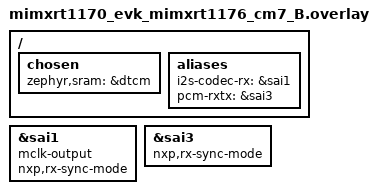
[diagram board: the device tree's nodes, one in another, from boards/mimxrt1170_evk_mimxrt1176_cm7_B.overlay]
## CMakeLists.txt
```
#SPDX - License - Identifier : Apache - 2.0

cmake_minimum_required(VERSION 3.28.0)
find_package(Zephyr REQUIRED HINTS $ENV{ZEPHYR_BASE})
project(handsfree_ag)

FILE(GLOB app_sources src/*.c)
target_sources(app PRIVATE ${app_sources})

include(${CMAKE_CURRENT_SOURCE_DIR}/../common/common.cmake)

zephyr_library_include_directories(${ZEPHYR_BASE}/samples/bluetooth)
```

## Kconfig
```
#
# Copyright 2024-2025 NXP
#
# SPDX-License-Identifier: Apache-2.0
#

mainmenu "Bluetooth: handsfree AG"

config BT_HFP_AG_DISCOVER_RESULT_COUNT
	int "Maximum result count per device discovery"
	default 10

config BT_HFP_AG_CALL_OUTGOING
	bool "The simulate call: outgoing (y), incoming (n)"

config BT_HFP_AG_START_CALL_DELAY_TIME
	int "The delay time used to start simulating a call after AG connection"
	default 5000
	help
	  The Delay time is used to wait for the peer to start dialing. If the
	  peer does not dial within the timeout period, AG satrt simulating a
	  call. The unit is ms.

source "Kconfig.zephyr"

choice HFP_AUDIO_PATH
	prompt "HFP audio data path"
	default HFP_AUDIO_PATH_SCO_HCI if SOC_SERIES_SF32LB52X
	default HFP_AUDIO_PATH_PCM
	help
	  Select the audio data path used for HFP voice streaming.

config HFP_AUDIO_PATH_PCM
	bool "PCM/I2S interface to controller"
	help
	  Route voice data through PCM/I2S pins on the Bluetooth controller.
	  Requires devicetree aliases for pcm-rxtx or pcm-rx/pcm-tx and
	  i2s-codec-rx/i2s-codec-tx.

config HFP_AUDIO_PATH_SCO_HCI
	bool "SCO over HCI transport"
	select BT_SCO_OVER_HCI
	help
	  Route voice data as SCO packets over the HCI transport between
	  the host and controller. Required for controllers without PCM pins,
	  such as the SiFli SF32LB52.

endchoice

config HFP_SCO_HCI_MSBC
	bool "Enable mSBC wideband codec for SCO over HCI"
	depends on HFP_AUDIO_PATH_SCO_HCI
	select LIBSBC
	default y if BT_HFP_AG_CODEC_MSBC
	help
	  Enable mSBC encode/decode for wideband voice when the SCO air mode
	  is transparent. Requires CONFIG_BT_HFP_AG_CODEC_NEG and
	  CONFIG_BT_HFP_AG_CODEC_MSBC for codec negotiation with the peer.

config HFP_SCO_HCI_THREAD_STACK_SIZE
	int "SCO over HCI audio thread stack size"
	depends on HFP_AUDIO_PATH_SCO_HCI
	default 2048

config HFP_SCO_HCI_THREAD_PRIO
	int "SCO over HCI audio thread priority"
	depends on HFP_AUDIO_PATH_SCO_HCI
	default 4

config AUDIO_TRANSFER_INTERVAL
	int "Audio transfer interval"
	default 10
	range 1 100
	help
	  Controls the audio transfer interval.

config PCM_BUFFERS
	int "PCM Buffer Count"
	default 4
	help
	  Controls the initial count of audio data blocks.

config PCM_RX_THREAD_STACK_SIZE
	int "PCM RX thread stack size"
	default 1024
	help
	  Controls the PCM RX thread stack size in bytes.

config PCM_RX_THREAD_PRIO
	int "PCM RX thread priority"
	default 4
	help
	  Controls the PCM RX thread priority.

config CODEC_BUFFERS
	int "CODEC Buffer Count"
	default PCM_BUFFERS
	help
	  Controls the initial count of audio data blocks.

config CODEC_RX_THREAD_STACK_SIZE
	int "CODEC RX thread stack size"
	default 1024
	help
	  Controls the CODEC RX thread stack size in bytes.

config CODEC_RX_THREAD_PRIO
	int "CODEC RX thread priority"
	default 4
	help
	  Controls the CODEC RX thread priority.
```

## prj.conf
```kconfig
CONFIG_BT=y
CONFIG_BT_CLASSIC=y
CONFIG_BT_RFCOMM=y
CONFIG_BT_HFP_AG=y
CONFIG_BT_CENTRAL=y
CONFIG_BT_DEVICE_NAME="Handsfree-ag"
```

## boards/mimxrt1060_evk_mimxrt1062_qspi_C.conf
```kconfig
CONFIG_AUDIO=y
CONFIG_I2S=y
CONFIG_AUDIO_CODEC=y

CONFIG_BT_HFP_AG_CODEC_NEG=y
CONFIG_BT_HFP_AG_CODEC_MSBC=y

CONFIG_DMA_MCUX_USE_DTCM_FOR_DMA_DESCRIPTORS=n
```

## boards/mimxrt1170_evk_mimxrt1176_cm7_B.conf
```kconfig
#select NXP NW612 Chipset
CONFIG_BT_NXP_NW612=y

CONFIG_I2S=y
CONFIG_AUDIO=y
CONFIG_AUDIO_CODEC=y

CONFIG_BT_HFP_AG_CODEC_NEG=y
CONFIG_BT_HFP_AG_CODEC_MSBC=y

CONFIG_DMA_MCUX_USE_DTCM_FOR_DMA_DESCRIPTORS=n
```

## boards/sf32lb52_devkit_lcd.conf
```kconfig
CONFIG_BT_CLASSIC=y
CONFIG_BT_RFCOMM=y
CONFIG_BT_HFP_AG=y
CONFIG_BT_CENTRAL=y
CONFIG_BT_DEVICE_NAME="test-Handsfree-AG"
CONFIG_BT_COD=0x400408

CONFIG_BT_SCO_OVER_HCI=y
CONFIG_BT_HFP_AG_CODEC_NEG=y
CONFIG_BT_HFP_AG_CODEC_MSBC=y
CONFIG_HFP_SCO_HCI_MSBC=y
CONFIG_LIBSBC=y
CONFIG_HEAP_MEM_POOL_SIZE=32000
CONFIG_AUDIO=y
CONFIG_AUDIO_CODEC=y
CONFIG_CRC_HW_HANDLER=n
```

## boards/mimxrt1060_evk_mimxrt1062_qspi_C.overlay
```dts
/*
 * SPDX-FileCopyrightText: Copyright The Zephyr Project Contributors
 *
 * SPDX-License-Identifier: Apache-2.0
 */

/ {
	aliases {
		i2s-codec-rx = &sai1;
		pcm-rxtx = &sai2;
	};
};

/* SAI1 already has pinctrl-0 set in board dtsi, just add our properties */
&sai1 {
	status = "okay";
	mclk-output;
	nxp,rx-sync-mode;
};

/*
 * SAI2 has pinctrl set in board dtsi, Enable SAI2 as duplex PCM interface
 * for HFP SCO audio
 */
&sai2 {
	status = "okay";
	nxp,tx-channel = <1>;
	nxp,rx-sync-mode;
};
```

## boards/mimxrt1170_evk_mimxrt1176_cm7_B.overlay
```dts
/*
 * Copyright 2024-2025 NXP
 *
 * SPDX-License-Identifier: Apache-2.0
 */

/ {
	chosen {
		zephyr,sram = &dtcm;
	};

	aliases {
		i2s-codec-rx = &sai1;
		pcm-rxtx = &sai3;
	};
};

&sai1 {
	mclk-output;
	nxp,rx-sync-mode;
	status = "okay";
};

&sai3 {
	nxp,rx-sync-mode;
	status = "okay";
};
```

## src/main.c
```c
/* main.c - Application main entry point */

/*
 * Copyright 2024-2026 NXP
 *
 * SPDX-License-Identifier: Apache-2.0
 */

#include <zephyr/types.h>
#include <stddef.h>
#include <string.h>
#include <errno.h>
#include <zephyr/sys/printk.h>
#include <zephyr/sys/byteorder.h>
#include <zephyr/kernel.h>

#include <zephyr/bluetooth/bluetooth.h>
#include <zephyr/bluetooth/conn.h>
#include <zephyr/bluetooth/l2cap.h>
#include <zephyr/bluetooth/hci.h>
#include <zephyr/bluetooth/classic/rfcomm.h>
#include <zephyr/bluetooth/classic/sdp.h>
#include <zephyr/bluetooth/classic/hfp_ag.h>
#include <zephyr/settings/settings.h>

#if defined(CONFIG_HFP_AUDIO_PATH_SCO_HCI)
#include "sco_hci.h"
#else
#include "pcm.h"
#include "codec.h"
#endif

static struct bt_conn *default_conn;
static struct bt_hfp_ag *hfp_ag;
static struct bt_conn *active_sco_conn;
static struct bt_hfp_ag_call *hfp_ag_call;

static struct bt_br_discovery_param br_discover;
static struct bt_br_discovery_result scan_result[CONFIG_BT_HFP_AG_DISCOVER_RESULT_COUNT];

static struct k_work discover_work;
static struct k_work_delayable call_connect_work;
static struct k_work_delayable call_disconnect_work;

static struct k_work_delayable call_remote_ringing_work;
static struct k_work_delayable call_remote_accept_work;

NET_BUF_POOL_DEFINE(sdp_discover_pool, 10, BT_L2CAP_BUF_SIZE(CONFIG_BT_L2CAP_TX_MTU),
		    CONFIG_BT_CONN_TX_USER_DATA_SIZE, NULL);

static void ag_connected(struct bt_conn *conn, struct bt_hfp_ag *ag)
{
	if (conn != default_conn) {
		printk("The conn %p is not aligned with ACL conn %p", conn, default_conn);
	}

	if (!hfp_ag) {
		hfp_ag = ag;
	}
	printk("HFP AG connected!\n");
	k_work_schedule(&call_connect_work, K_MSEC(CONFIG_BT_HFP_AG_START_CALL_DELAY_TIME));
}

static void ag_disconnected(struct bt_hfp_ag *ag)
{
	printk("HFP AG disconnected!\n");
}

#if !defined(CONFIG_HFP_AUDIO_PATH_SCO_HCI)
static void pcm_rx_cb(const uint8_t *data, uint32_t len)
{
	int err;

	if (active_sco_conn == NULL) {
		return;
	}

	err = codec_tx(data, len);
	if (err != 0) {
		printk("Failed to transmit PCM data: %d\n", err);
	}
}

static void codec_rx_cb(const uint8_t *data, uint32_t len)
{
	int err;

	if (active_sco_conn == NULL) {
		return;
	}

	err = pcm_tx(data, len);
	if (err != 0) {
		printk("Failed to transmit Codec data: %d\n", err);
	}
}
#endif /* !CONFIG_HFP_AUDIO_PATH_SCO_HCI */

static void ag_sco_connected(struct bt_hfp_ag *ag, struct bt_conn *sco_conn)
{
	struct bt_conn_info info;
	int err;

	printk("AG SCO connected\n");
	active_sco_conn = bt_conn_ref(sco_conn);

	err = bt_conn_get_info(sco_conn, &info);
	if (err != 0) {
		printk("Failed to get sco conn %p info\n", sco_conn);
		return;
	}

	printk("SCO air mode %u\n", info.sco.air_mode);

#if defined(CONFIG_HFP_AUDIO_PATH_SCO_HCI)
	err = sco_hci_init(info.sco.air_mode);
	if (err != 0) {
		printk("Failed to initialize SCO over HCI for air mode %u\n", info.sco.air_mode);
		return;
	}

	err = sco_hci_start(sco_conn);
	if (err != 0) {
		printk("Failed to start SCO over HCI\n");
		return;
	}
#else
	err = pcm_init(info.sco.air_mode);
	if (err != 0) {
		printk("Failed to initialize PCM for air mode %u\n", info.sco.air_mode);
		return;
	}

	err = codec_init(info.sco.air_mode);
	if (err != 0) {
		printk("Failed to initialize CODEC for air mode %u\n", info.sco.air_mode);
		return;
	}

	err = pcm_rx_start(pcm_rx_cb);
	if (err != 0) {
		printk("Failed to start PCM\n");
		return;
	}

	err = codec_rx_start(codec_rx_cb);
	if (err != 0) {
		printk("Failed to start CODEC\n");
		return;
	}
#endif
}

static void ag_sco_disconnected(struct bt_conn *sco_conn, uint8_t reason)
{
	int err;

	if (active_sco_conn != sco_conn) {
		return;
	}

	bt_conn_drop(&active_sco_conn);

#if defined(CONFIG_HFP_AUDIO_PATH_SCO_HCI)
	err = sco_hci_stop();
	if (err != 0) {
		printk("Failed to stop SCO over HCI\n");
	}
#else
	err = pcm_rx_stop();
	if (err != 0) {
		printk("Failed to stop PCM\n");
	}

	err = codec_rx_stop();
	if (err != 0) {
		printk("Failed to stop CODEC\n");
	}
#endif

	printk("HFP AG SCO disconnected %u!\n", reason);
}

static void ag_ringing(struct bt_hfp_ag_call *call, bool in_band)
{
	printk("Ringing (in bond? %s)\n", in_band ? "Yes" : "No");
}

static void ag_accept(struct bt_hfp_ag_call *call)
{
	printk("Call Accepted\n");
	/* Keep the simulated call up long enough to verify SCO audio */
	k_work_schedule(&call_disconnect_work, K_SECONDS(60));
}

static void ag_reject(struct bt_hfp_ag_call *call)
{
	printk("Call Rejected\n");
	k_work_schedule(&call_disconnect_work, K_SECONDS(1));
}

static void ag_terminate(struct bt_hfp_ag_call *call)
{
	printk("Call terminated\n");
	k_work_schedule(&call_disconnect_work, K_SECONDS(1));
}

static void ag_outgoing(struct bt_hfp_ag *ag, struct bt_hfp_ag_call *call, const char *number)
{
	hfp_ag_call = call;
	printk("Call outgoing, remote number %s\n", number);
	k_work_cancel_delayable(&call_connect_work);
	k_work_schedule(&call_remote_ringing_work, K_SECONDS(1));
}

static void ag_incoming(struct bt_hfp_ag *ag, struct bt_hfp_ag_call *call, const char *number)
{
	hfp_ag_call = call;
	printk("Incoming call, remote number %s\n", number);
	k_work_cancel_delayable(&call_connect_work);
}

#if defined(CONFIG_BT_HFP_AG_CODEC_NEG)
static void ag_codec(struct bt_hfp_ag *ag, uint32_t ids)
{
	printk("AG received codec id bit map %x\n", ids);
}

static void ag_codec_negotiate(struct bt_hfp_ag *ag, int err)
{
	printk("AG codec negotiation result %d\n", err);
}
#endif /* CONFIG_BT_HFP_AG_CODEC_NEG */

static struct bt_hfp_ag_cb ag_cb = {
	.connected = ag_connected,
	.disconnected = ag_disconnected,
	.sco_connected = ag_sco_connected,
	.sco_disconnected = ag_sco_disconnected,
	.outgoing = ag_outgoing,
	.incoming = ag_incoming,
	.ringing = ag_ringing,
	.accept = ag_accept,
	.reject = ag_reject,
	.terminate = ag_terminate,
#if defined(CONFIG_BT_HFP_AG_CODEC_NEG)
	.codec = ag_codec,
	.codec_negotiate = ag_codec_negotiate,
#endif /* CONFIG_BT_HFP_AG_CODEC_NEG */
};

static uint8_t sdp_discover_cb(struct bt_conn *conn, struct bt_sdp_client_result *result,
			       const struct bt_sdp_discover_params *params)
{
	int err;
	uint16_t value;

	printk("Discover done\n");

	if (result->resp_buf != NULL) {
		err = bt_sdp_get_proto_param(result->resp_buf, BT_SDP_PROTO_RFCOMM, &value);

		if (err != 0) {
			printk("Fail to parser RFCOMM the SDP response!\n");
		} else {
			printk("The server channel is %d\n", value);
			err = bt_hfp_ag_connect(conn, &hfp_ag, value);
			if (err != 0) {
				printk("Fail to create hfp AG connection (err %d)\n", err);
			}
		}
	}

	return BT_SDP_DISCOVER_UUID_STOP;
}

static struct bt_sdp_discover_params sdp_discover = {
	.type = BT_SDP_DISCOVER_SERVICE_SEARCH_ATTR,
	.func = sdp_discover_cb,
	.pool = &sdp_discover_pool,
	.uuid = BT_UUID_DECLARE_16(BT_SDP_HANDSFREE_SVCLASS),
};

static void connected(struct bt_conn *conn, uint8_t err)
{
	int res;

	if (err) {
		if (default_conn != NULL) {
			default_conn = NULL;
		}
		printk("Connection failed, err 0x%02x %s\n", err, bt_hci_err_to_str(err));
	} else {
		if (default_conn == conn) {
			struct bt_conn_info info;

			bt_conn_get_info(conn, &info);
			if (info.type != BT_CONN_TYPE_BR) {
				return;
			}

			/*
			 * Do an SDP Query on Successful ACL connection complete with the
			 * required device
			 */
			res = bt_sdp_discover(default_conn, &sdp_discover);
			if (res) {
				printk("SDP discovery failed (err %d)\r\n", res);
			} else {
				printk("SDP discovery started\r\n");
			}
			printk("Connected\n");
		}
	}
}

static void disconnected(struct bt_conn *conn, uint8_t reason)
{
	printk("Disconnected, reason 0x%02x %s\n", reason, bt_hci_err_to_str(reason));

	if (default_conn != conn) {
		return;
	}

	if (default_conn) {
		default_conn = NULL;
	} else {
		return;
	}
}

static void security_changed(struct bt_conn *conn, bt_security_t level, enum bt_security_err err)
{
	struct bt_conn_info info;

	bt_conn_get_info(conn, &info);

	printk("Security changed: %s level %u, err %s(%d)\n", bt_addr_str(info.br.dst), level,
	       bt_security_err_to_str(err), err);
}

static struct bt_conn_cb conn_callbacks = {
	.connected = connected,
	.disconnected = disconnected,
	.security_changed = security_changed,
};

static void discovery_recv_cb(const struct bt_br_discovery_result *result)
{
	(void)result;
}

static void discovery_timeout_cb(const struct bt_br_discovery_result *results, size_t count)
{
	const struct bt_br_discovery_result *best_hf = NULL;
	static uint8_t temp[240];
	size_t i;

	for (i = 0; i < count; i++) {
		const uint8_t *eir = results[i].eir;
		size_t len = sizeof(results[i].eir);
		uint8_t major_device = (uint8_t)BT_COD_MAJOR_DEVICE_CLASS(results[i].cod);
		uint8_t minor_device = (uint8_t)BT_COD_MINOR_DEVICE_CLASS(results[i].cod);
		bool is_hf = (major_device & BT_COD_MAJOR_DEVICE_CLASS_AUDIO_VIDEO) &&
			     (minor_device & BT_COD_MINOR_DEVICE_CLASS_AUDIO_VIDEO_HANDSFREE);

		printk("Device[%d]: %s, rssi %d, cod 0x%02x%02x%02x", i,
		       bt_addr_str(&results[i].addr), results[i].rssi,
		       results[i].cod[0], results[i].cod[1], results[i].cod[2]);

		while ((eir[0] > 2) && (len > eir[0])) {
			switch (eir[1]) {
			case BT_DATA_NAME_SHORTENED:
			case BT_DATA_NAME_COMPLETE:
				memcpy(temp, &eir[2], eir[0] - 1);
				temp[eir[0] - 1] = '\0'; /* Set end flag */
				printk(", name %s", temp);
				break;
			default:
				/* Skip the EIR */
				break;
			}
			len = len - eir[0] - 1;
			eir = eir + eir[0] + 1;
		}
		printk("%s\n", is_hf ? ", Handsfree" : "");

		if (is_hf && (best_hf == NULL || results[i].rssi > best_hf->rssi)) {
			best_hf = &results[i];
		}
	}

	if (best_hf == NULL) {
		(void)k_work_submit(&discover_work);
		return;
	}

	(void)k_work_cancel(&discover_work);
	printk("Connecting to Handsfree %s (rssi %d)\n", bt_addr_str(&best_hf->addr),
	       best_hf->rssi);

	default_conn = bt_conn_create_br(&best_hf->addr, BT_BR_CONN_PARAM_DEFAULT);
	if (default_conn == NULL) {
		printk("Fail to create the connecton\n");
	} else {
		bt_conn_unref(default_conn);
	}
}

static void discover_work_handler(struct k_work *work)
{
	int err;

	br_discover.length = 10;
	br_discover.limited = false;

	err = bt_br_discovery_start(&br_discover, scan_result,
				    CONFIG_BT_HFP_AG_DISCOVER_RESULT_COUNT);
	if (err) {
		printk("Fail to start discovery (err %d)\n", err);
		return;
	}
}

static void call_connect_work_handler(struct k_work *work)
{
#if CONFIG_BT_HFP_AG_CALL_OUTGOING
	int err;

	printk("Dialing\n");

	err = bt_hfp_ag_outgoing(hfp_ag, "test_hf");

	if (err != 0) {
		printk("Fail to dial a call (err %d)\n", err);
	}
#else
	int err = bt_hfp_ag_remote_incoming(hfp_ag, "test_hf");

	if (err != 0) {
		printk("Fail to set remote incoming call (err %d)\n", err);
	}
#endif /* CONFIG_BT_HFP_AG_CALL_OUTGOING */
}

static void call_disconnect_work_handler(struct k_work *work)
{
	int err;

	if (default_conn != NULL) {
		err = bt_conn_disconnect(default_conn, BT_HCI_ERR_REMOTE_USER_TERM_CONN);

		if (err != 0) {
			printk("Fail to disconnect acl connection (err %d)\n", err);
		}
	}
}

static void call_remote_ringing_work_handler(struct k_work *work)
{
	int err;

	printk("Remote starts ringing\n");

	err = bt_hfp_ag_remote_ringing(hfp_ag_call);

	if (err != 0) {
		printk("Fail to notify hfp unit that the remote starts ringing (err %d)\n", err);
	} else {
		k_work_schedule(&call_remote_accept_work, K_SECONDS(1));
	}
}

static void call_remote_accept_work_handler(struct k_work *work)
{
	int err;

	printk("Remote accepts the call\n");

	err = bt_hfp_ag_remote_accept(hfp_ag_call);

	if (err != 0) {
		printk("Fail to notify hfp unit that the remote accepts call (err %d)\n", err);
	}
}

static struct bt_br_discovery_cb discovery_cb = {
	.recv = discovery_recv_cb,
	.timeout = discovery_timeout_cb,
};

static void bt_ready(int err)
{
	if (err) {
		printk("Bluetooth init failed (err %d)\n", err);
		return;
	}

	if (IS_ENABLED(CONFIG_SETTINGS)) {
		settings_load();
	}

	printk("Bluetooth initialized\n");

	bt_conn_cb_register(&conn_callbacks);

	bt_br_discovery_cb_register(&discovery_cb);

	bt_hfp_ag_register(&ag_cb);

	k_work_init(&discover_work, discover_work_handler);

	(void)k_work_submit(&discover_work);

	k_work_init_delayable(&call_connect_work, call_connect_work_handler);
	k_work_init_delayable(&call_disconnect_work, call_disconnect_work_handler);

	k_work_init_delayable(&call_remote_ringing_work, call_remote_ringing_work_handler);
	k_work_init_delayable(&call_remote_accept_work, call_remote_accept_work_handler);
}

int main(void)
{
	int err;

	printk("Bluetooth Handsfree AG demo start...\n");

	err = bt_enable(bt_ready);
	if (err) {
		printk("Bluetooth init failed (err %d)\n", err);
	}
	return 0;
}
```

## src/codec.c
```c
/* codec.c - CODEC implementation for Bluetooth Hands-Free Profile */

/*
 * Copyright 2025 NXP
 *
 * SPDX-License-Identifier: Apache-2.0
 */

#include <zephyr/kernel.h>
#include <zephyr/sys/printk.h>
#include <zephyr/drivers/i2s.h>
#include <zephyr/audio/codec.h>
#include <zephyr/toolchain.h>

#include <zephyr/bluetooth/bluetooth.h>

#include "codec.h"

#if DT_HAS_ALIAS(i2s_codec_tx) && DT_HAS_ALIAS(i2s_codec_rx)
#define I2S_CODEC_TX DT_ALIAS(i2s_codec_tx)
#define I2S_CODEC_RX DT_ALIAS(i2s_codec_rx)
#define I2C_CODEC    DT_NODELABEL(audio_codec)

#define MAX_SAMPLE_FREQ      16000
#define MAX_SAMPLE_BIT_WIDTH 16
#define MAX_CHANNELS         2

#define SAMPLES_PER_BLOCK ((MAX_SAMPLE_FREQ * CONFIG_AUDIO_TRANSFER_INTERVAL / 1000) * MAX_CHANNELS)

#define BLOCK_SIZE     (MAX_SAMPLE_BIT_WIDTH * SAMPLES_PER_BLOCK / 8)
#define RX_BLOCK_COUNT (CONFIG_CODEC_BUFFERS)
#define TX_BLOCK_COUNT (CONFIG_CODEC_BUFFERS)
#define TIMEOUT        (2 * 1000 / CONFIG_AUDIO_TRANSFER_INTERVAL)

static const struct device *i2s_codec_tx = DEVICE_DT_GET(I2S_CODEC_TX);
static const struct device *i2s_codec_rx = DEVICE_DT_GET(I2S_CODEC_RX);
static const struct device *i2c_codec = DEVICE_DT_GET(I2C_CODEC);

K_MEM_SLAB_DEFINE_IN_SECT_STATIC(tx_mem_slab, __nocache, BLOCK_SIZE, TX_BLOCK_COUNT, 4);
K_MEM_SLAB_DEFINE_IN_SECT_STATIC(rx_mem_slab, __nocache, BLOCK_SIZE, RX_BLOCK_COUNT, 4);

static int configure_codec_streams(const struct device *i2s_codec_rx,
				   const struct device *i2s_codec_tx, struct i2s_config *config)
{
	int err;

	config->mem_slab = &rx_mem_slab;
	err = i2s_configure(i2s_codec_rx, I2S_DIR_RX, config);
	if (err < 0) {
		printk("Failed to configure CODEC RX stream: %d\n", err);
		return err;
	}

	config->mem_slab = &tx_mem_slab;
	err = i2s_configure(i2s_codec_tx, I2S_DIR_TX, config);
	if (err < 0) {
		printk("Failed to configure CODEC TX stream: %d\n", err);
		return err;
	}

	return 0;
}

static struct k_sem codec_rx_thread_notify;
static codec_rx_cb_t codec_rx_cb;

#define CODEC_RX_FLAG_STOPPED  0
#define CODEC_RX_FLAG_STARTED  1
#define CODEC_RX_FLAG_STOPPING 2

static atomic_t codec_rx_flag[1];

static void codec_rx_task(void *p1, void *p2, void *p3)
{
	int err;
	void *mem_block;
	uint32_t block_size;

	while (true) {
		err = k_sem_take(&codec_rx_thread_notify, K_FOREVER);
		if (err < 0) {
			continue;
		}

		if (atomic_test_and_clear_bit(codec_rx_flag, CODEC_RX_FLAG_STOPPING)) {
			err = i2s_trigger(i2s_codec_rx, I2S_DIR_RX, I2S_TRIGGER_STOP);
			if (err < 0) {
				printk("Failed to stop CODEC RX %d\n", err);
			}
			atomic_clear_bit(codec_rx_flag, CODEC_RX_FLAG_STARTED);
			atomic_set_bit(codec_rx_flag, CODEC_RX_FLAG_STOPPED);
		}

		if (!atomic_test_bit(codec_rx_flag, CODEC_RX_FLAG_STARTED)) {
			continue;
		} else {
			k_sem_give(&codec_rx_thread_notify);
		}

		err = i2s_read(i2s_codec_rx, &mem_block, &block_size);
		if (err < 0) {
			continue;
		}

		if (codec_rx_cb != NULL) {
			codec_rx_cb(mem_block, block_size);
		}
		k_mem_slab_free(&rx_mem_slab, (void *)mem_block);
	}
}

static K_KERNEL_STACK_MEMBER(codec_rx_thread_stack, CONFIG_CODEC_RX_THREAD_STACK_SIZE);

int codec_init(uint8_t air_mode)
{
	struct i2s_config config = {0};
	struct audio_codec_cfg audio_cfg;
	int err;
	uint8_t word_size;
	uint8_t channels;
	uint32_t sample_rate;

	static bool is_initiated;
	static struct k_thread codec_rx_thread;
	static k_tid_t codec_rx_thread_id;

	if (is_initiated) {
		return 0;
	}

	if (!device_is_ready(i2s_codec_rx)) {
		printk("%s is not ready\n", i2s_codec_rx->name);
		return -EINVAL;
	}

	if (i2s_codec_rx != i2s_codec_tx && !device_is_ready(i2s_codec_tx)) {
		printk("%s is not ready\n", i2s_codec_tx->name);
		return -EINVAL;
	}

	if (!device_is_ready(i2c_codec)) {
		printk("%s is not ready\n", i2c_codec->name);
		return -EINVAL;
	}

	switch (air_mode) {
	case BT_HCI_CODING_FORMAT_CVSD:
		word_size = 16;
		channels = 2;
		sample_rate = 8000;
		break;
	case BT_HCI_CODING_FORMAT_TRANSPARENT:
		word_size = 16;
		channels = 2;
		sample_rate = 16000;
		break;
	case BT_HCI_CODING_FORMAT_ULAW_LOG:
	case BT_HCI_CODING_FORMAT_ALAW_LOG:
	case BT_HCI_CODING_FORMAT_LINEAR_PCM:
	case BT_HCI_CODING_FORMAT_MSBC:
	case BT_HCI_CODING_FORMAT_LC3:
	case BT_HCI_CODING_FORMAT_G729A:
	case BT_HCI_CODING_FORMAT_VS:
	default:
		printk("Unsupported air mode: %d\n", air_mode);
		return -ENOTSUP;
	}

	audio_cfg.dai_route = AUDIO_ROUTE_PLAYBACK_CAPTURE;
	audio_cfg.dai_type = AUDIO_DAI_TYPE_I2S;
	audio_cfg.dai_cfg.i2s.word_size = word_size;
	audio_cfg.dai_cfg.i2s.channels = channels;
	audio_cfg.dai_cfg.i2s.format = I2S_FMT_DATA_FORMAT_I2S;
	audio_cfg.dai_cfg.i2s.options = I2S_OPT_FRAME_CLK_TARGET | I2S_OPT_BIT_CLK_TARGET;
	audio_cfg.dai_cfg.i2s.frame_clk_freq = sample_rate;
	audio_cfg.dai_cfg.i2s.mem_slab = &rx_mem_slab;
	audio_cfg.dai_cfg.i2s.block_size = BLOCK_SIZE;
	err = audio_codec_configure(i2c_codec, &audio_cfg);
	if (err != 0) {
		printk("Failed to configure audio codec: %d\n", err);
		return err;
	}

	config.word_size = word_size;
	config.channels = channels;
	config.format = I2S_FMT_DATA_FORMAT_I2S;
	config.options = I2S_OPT_FRAME_CLK_CONTROLLER | I2S_OPT_BIT_CLK_CONTROLLER;
	config.frame_clk_freq = sample_rate;
	config.block_size = BLOCK_SIZE;
	config.timeout = TIMEOUT;

	err = configure_codec_streams(i2s_codec_rx, i2s_codec_tx, &config);
	if (err < 0) {
		return err;
	}

	if (codec_rx_thread_id == NULL) {
		k_sem_init(&codec_rx_thread_notify, 0, 1);
		codec_rx_thread_id = k_thread_create(&codec_rx_thread, codec_rx_thread_stack,
						     K_KERNEL_STACK_SIZEOF(codec_rx_thread_stack),
						     codec_rx_task, NULL, NULL, NULL,
						     K_PRIO_COOP(CONFIG_CODEC_RX_THREAD_PRIO), 0,
						     K_NO_WAIT);
		k_thread_name_set(codec_rx_thread_id, "HFP CODEC RX");
	}

	atomic_set_bit(codec_rx_flag, CODEC_RX_FLAG_STOPPED);
	is_initiated = true;

	return 0;
}

int codec_rx_start(codec_rx_cb_t cb)
{
	int err;

	if (!atomic_test_bit(codec_rx_flag, CODEC_RX_FLAG_STOPPED)) {
		printk("CODEC RX is not idle\n");
		return -EBUSY;
	}

	codec_rx_cb = cb;

	err = i2s_trigger(i2s_codec_rx, I2S_DIR_RX, I2S_TRIGGER_START);
	if (err < 0) {
		printk("Failed to trigger start on RX: %d\n", err);
		return err;
	}

	atomic_clear_bit(codec_rx_flag, CODEC_RX_FLAG_STOPPED);
	atomic_set_bit(codec_rx_flag, CODEC_RX_FLAG_STARTED);
	k_sem_give(&codec_rx_thread_notify);

	return 0;
}

int codec_rx_stop(void)
{
	if (!atomic_test_bit(codec_rx_flag, CODEC_RX_FLAG_STARTED)) {
		return 0;
	}

	atomic_set_bit(codec_rx_flag, CODEC_RX_FLAG_STOPPING);
	k_sem_give(&codec_rx_thread_notify);

	return 0;
}

int codec_tx(const uint8_t *data, uint32_t len)
{
	int err;
	void *mem_block;

	if (len * 2 != BLOCK_SIZE) {
		printk("Invalid data len %u != %u\n", len, BLOCK_SIZE / 2);
		return -EINVAL;
	}

	err = k_mem_slab_alloc(&tx_mem_slab, &mem_block, K_NO_WAIT);
	if (err < 0) {
		printk("Failed to allocate TX block: %d\n", err);
		return err;
	}

	for (uint32_t i = 0; i < len; i += 2) {
		uint32_t *dst;
		uint16_t *src;

		dst = (uint32_t *)&((uint8_t *)mem_block)[i * 2];
		src = (uint16_t *)&data[i];

		*dst = (*src) | ((*src) << 16);
	}

	err = i2s_write(i2s_codec_tx, mem_block, BLOCK_SIZE);
	if (err < 0) {
		k_mem_slab_free(&tx_mem_slab, mem_block);
		printk("Failed to write block: %d\n", err);
		return err;
	}

	/* Try to trigger TX start each time, because TX may have stopped if there is no more
	 * data in pending.
	 * Ignore the error.
	 */
	(void)i2s_trigger(i2s_codec_tx, I2S_DIR_TX, I2S_TRIGGER_START);

	return 0;
}

#else

int codec_init(uint8_t air_mode)
{
	printk("Codec is unsupported\n");
	return 0;
}

int codec_tx(const uint8_t *data, uint32_t len)
{
	return 0;
}

int codec_rx_start(codec_rx_cb_t cb)
{
	return 0;
}

int codec_rx_stop(void)
{
	return 0;
}

#endif /* DT_HAS_ALIAS(i2s_codec_tx) && DT_HAS_ALIAS(i2s_codec_rx) */
```

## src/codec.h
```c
/* codec.h - CODEC implementation for Bluetooth Hands-Free Profile */

/*
 * Copyright 2025 NXP
 *
 * SPDX-License-Identifier: Apache-2.0
 */

#ifndef _ZEPHYR_SAMPLES_CLASSIC_HANDSFREE_CODEC_H_
#define _ZEPHYR_SAMPLES_CLASSIC_HANDSFREE_CODEC_H_

#include <stdint.h>

typedef void (*codec_rx_cb_t)(const uint8_t *data, uint32_t len);

int codec_init(uint8_t air_mode);
int codec_tx(const uint8_t *data, uint32_t len);
int codec_rx_start(codec_rx_cb_t cb);
int codec_rx_stop(void);

#endif /* _ZEPHYR_SAMPLES_CLASSIC_HANDSFREE_CODEC_H_ */
```

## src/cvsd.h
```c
/*
 * Copyright (c) 2025 SiFli Technologies(Nanjing) Co., Ltd
 *
 * SPDX-License-Identifier: Apache-2.0
 */

#ifndef CVSD_H_
#define CVSD_H_

#include <stddef.h>
#include <stdint.h>

struct cvsd_ctx {
	int32_t accum;
	int16_t prev;
};

void cvsd_init(struct cvsd_ctx *ctx);
void cvsd_decode(struct cvsd_ctx *ctx, const uint8_t *in, size_t in_len, int16_t *out);
void cvsd_encode(struct cvsd_ctx *ctx, const int16_t *in, size_t samples, uint8_t *out);

#endif /* CVSD_H_ */
```

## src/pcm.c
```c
/* pcm.c - PCM implementation for Bluetooth Hands-Free Profile */

/*
 * Copyright 2025 NXP
 *
 * SPDX-License-Identifier: Apache-2.0
 */

#include <zephyr/kernel.h>
#include <zephyr/sys/printk.h>
#include <zephyr/drivers/i2s.h>
#include <zephyr/toolchain.h>

#include <zephyr/bluetooth/bluetooth.h>

#include "pcm.h"

#if DT_HAS_ALIAS(pcm_rxtx) || (DT_HAS_ALIAS(pcm_rx) && DT_HAS_ALIAS(pcm_tx))
#if DT_NODE_EXISTS(DT_ALIAS(pcm_rxtx))
#define PCM_RX DT_ALIAS(pcm_rxtx)
#define PCM_TX DT_ALIAS(pcm_rxtx)
#else
#define PCM_RX DT_ALIAS(pcm_rx)
#define PCM_TX DT_ALIAS(pcm_tx)
#endif

#define MAX_SAMPLE_FREQ      16000
#define MAX_SAMPLE_BIT_WIDTH 16
#define MAX_CHANNELS         1

#define SAMPLES_PER_BLOCK ((MAX_SAMPLE_FREQ * CONFIG_AUDIO_TRANSFER_INTERVAL / 1000) * MAX_CHANNELS)

#define BLOCK_SIZE     (MAX_SAMPLE_BIT_WIDTH * SAMPLES_PER_BLOCK / 8)
#define RX_BLOCK_COUNT (CONFIG_PCM_BUFFERS)
#define TX_BLOCK_COUNT (CONFIG_PCM_BUFFERS)
#define TIMEOUT        (2 * 1000 / CONFIG_AUDIO_TRANSFER_INTERVAL)

static const struct device *pcm_rx_dev = DEVICE_DT_GET(PCM_RX);
static const struct device *pcm_tx_dev = DEVICE_DT_GET(PCM_TX);

K_MEM_SLAB_DEFINE_IN_SECT_STATIC(rx_mem_slab, __nocache, BLOCK_SIZE, RX_BLOCK_COUNT, 4);
K_MEM_SLAB_DEFINE_IN_SECT_STATIC(tx_mem_slab, __nocache, BLOCK_SIZE, TX_BLOCK_COUNT, 4);

static int configure_pcm_streams(const struct device *pcm_rx_dev, const struct device *pcm_tx_dev,
				 struct i2s_config *config)
{
	int err;

	config->mem_slab = &rx_mem_slab;
	err = i2s_configure(pcm_rx_dev, I2S_DIR_RX, config);
	if (err < 0) {
		printk("Failed to configure PCM RX stream: %d\n", err);
		return err;
	}

	config->mem_slab = &tx_mem_slab;
	err = i2s_configure(pcm_tx_dev, I2S_DIR_TX, config);
	if (err < 0) {
		printk("Failed to configure PCM TX stream: %d\n", err);
		return err;
	}

	return 0;
}

static struct k_sem pcm_rx_thread_notify;
static pcm_rx_cb_t pcm_rx_cb;

#define PCM_RX_FLAG_STOPPED  0
#define PCM_RX_FLAG_STARTED  1

static atomic_t pcm_rx_flag[1];

static void pcm_rx_task(void *p1, void *p2, void *p3)
{
	int err;
	void *mem_block;
	uint32_t block_size;

	while (true) {
		err = k_sem_take(&pcm_rx_thread_notify, K_FOREVER);
		if (err < 0) {
			continue;
		}

		if (!atomic_test_bit(pcm_rx_flag, PCM_RX_FLAG_STARTED)) {
			continue;
		} else {
			k_sem_give(&pcm_rx_thread_notify);
		}

		err = i2s_read(pcm_rx_dev, &mem_block, &block_size);
		if (err < 0) {
			continue;
		}

		if (pcm_rx_cb != NULL) {
			pcm_rx_cb((const uint8_t *)mem_block, block_size);
		}
		k_mem_slab_free(&rx_mem_slab, (void *)mem_block);
	}
}

static K_KERNEL_STACK_MEMBER(pcm_rx_thread_stack, CONFIG_PCM_RX_THREAD_STACK_SIZE);

int pcm_init(uint8_t air_mode)
{
	struct i2s_config config = {0};
	int err;
	uint8_t word_size;
	uint8_t channels;
	uint32_t sample_rate;

	static bool is_initiated;
	static struct k_thread pcm_rx_thread;
	static k_tid_t pcm_rx_thread_id;

	if (is_initiated) {
		return 0;
	}

	if (!device_is_ready(pcm_rx_dev)) {
		printk("%s is not ready\n", pcm_rx_dev->name);
		return -EINVAL;
	}

	if (pcm_rx_dev != pcm_tx_dev && !device_is_ready(pcm_tx_dev)) {
		printk("%s is not ready\n", pcm_tx_dev->name);
		return -EINVAL;
	}

	switch (air_mode) {
	case BT_HCI_CODING_FORMAT_CVSD:
		word_size = 16;
		channels = 1;
		sample_rate = 8000;
		break;
	case BT_HCI_CODING_FORMAT_TRANSPARENT:
		word_size = 16;
		channels = 1;
		sample_rate = 16000;
		break;
	case BT_HCI_CODING_FORMAT_ULAW_LOG:
	case BT_HCI_CODING_FORMAT_ALAW_LOG:
	case BT_HCI_CODING_FORMAT_LINEAR_PCM:
	case BT_HCI_CODING_FORMAT_MSBC:
	case BT_HCI_CODING_FORMAT_LC3:
	case BT_HCI_CODING_FORMAT_G729A:
	case BT_HCI_CODING_FORMAT_VS:
	default:
		printk("Unsupported air mode: %d\n", air_mode);
		return -ENOTSUP;
	}

	config.word_size = word_size;
	config.channels = channels;
	config.format = I2S_FMT_DATA_FORMAT_PCM_SHORT;
	config.options = I2S_OPT_BIT_CLK_TARGET | I2S_OPT_FRAME_CLK_TARGET;
	config.frame_clk_freq = sample_rate;
	config.block_size = BLOCK_SIZE;
	config.timeout = TIMEOUT;

	err = configure_pcm_streams(pcm_rx_dev, pcm_tx_dev, &config);
	if (err < 0) {
		return err;
	}

	if (pcm_rx_thread_id == NULL) {
		k_sem_init(&pcm_rx_thread_notify, 0, 1);
		pcm_rx_thread_id = k_thread_create(&pcm_rx_thread, pcm_rx_thread_stack,
						   K_KERNEL_STACK_SIZEOF(pcm_rx_thread_stack),
						   pcm_rx_task, NULL, NULL, NULL,
						   K_PRIO_COOP(CONFIG_PCM_RX_THREAD_PRIO), 0,
						   K_NO_WAIT);
		k_thread_name_set(pcm_rx_thread_id, "HFP PCM RX");
	}

	atomic_set_bit(pcm_rx_flag, PCM_RX_FLAG_STOPPED);
	is_initiated = true;

	return 0;
}

int pcm_rx_start(pcm_rx_cb_t cb)
{
	int err;

	if (!atomic_test_bit(pcm_rx_flag, PCM_RX_FLAG_STOPPED)) {
		return 0;
	}

	pcm_rx_cb = cb;

	err = i2s_trigger(pcm_rx_dev, I2S_DIR_RX, I2S_TRIGGER_START);
	if (err < 0) {
		printk("Failed to trigger start on RX: %d\n", err);
		return err;
	}

	atomic_clear_bit(pcm_rx_flag, PCM_RX_FLAG_STOPPED);
	atomic_set_bit(pcm_rx_flag, PCM_RX_FLAG_STARTED);
	k_sem_give(&pcm_rx_thread_notify);

	return 0;
}

int pcm_rx_stop(void)
{
	/* TODO: Stop I2S RX. */
	return 0;
}

int pcm_tx(const uint8_t *data, uint32_t len)
{
	int err;
	void *mem_block;

	if (len != (BLOCK_SIZE * 2)) {
		printk("Invalid data len %u != %u\n", len, BLOCK_SIZE * 2);
		return -EINVAL;
	}

	err = k_mem_slab_alloc(&tx_mem_slab, &mem_block, K_NO_WAIT);
	if (err < 0) {
		printk("Failed to allocate TX block: %d\n", err);
		return err;
	}

	for (uint32_t i = 0; i < BLOCK_SIZE; i += 2) {
		uint16_t *dst;
		const uint16_t *src;

		dst = (uint16_t *)&((uint8_t *)mem_block)[i];
		src = (const uint16_t *)&data[i * 2 + 2];

		*dst = *src;
	}

	err = i2s_write(pcm_tx_dev, mem_block, BLOCK_SIZE);
	if (err < 0) {
		k_mem_slab_free(&tx_mem_slab, mem_block);
		printk("Failed to write block: %d\n", err);
		return err;
	}

	/* Try to trigger TX start each time, because TX may have stopped if there is no more
	 * data in pending.
	 * Ignore the error.
	 */
	(void)i2s_trigger(pcm_tx_dev, I2S_DIR_TX, I2S_TRIGGER_START);

	return 0;
}
#else
int pcm_init(uint8_t air_mode)
{
	printk("PCM is unsupported\n");
	return 0;
}

int pcm_tx(const uint8_t *data, uint32_t len)
{
	return 0;
}

int pcm_rx_start(pcm_rx_cb_t cb)
{
	return 0;
}

int pcm_rx_stop(void)
{
	return 0;
}
#endif /* DT_HAS_ALIAS(pcm_rxtx) || (DT_HAS_ALIAS(pcm_rx) && DT_HAS_ALIAS(pcm_tx)) */
```

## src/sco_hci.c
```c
/*
 * Copyright (c) 2025 SiFli Technologies(Nanjing) Co., Ltd
 *
 * SPDX-License-Identifier: Apache-2.0
 */

#include <errno.h>
#include <stdbool.h>
#include <stddef.h>
#include <stdint.h>
#include <string.h>

#include <zephyr/autoconf.h>
#include <zephyr/device.h>
#include <zephyr/devicetree.h>
#include <zephyr/kernel.h>
#include <zephyr/sys/printk.h>
#include <zephyr/bluetooth/classic/sco.h>
#include <zephyr/bluetooth/conn.h>
#include <zephyr/bluetooth/bluetooth.h>
#include <zephyr/bluetooth/hci_types.h>
#include <zephyr/audio/codec.h>
#include <zephyr/sys/ring_buffer.h>
#include <zephyr/sys/util.h>

#include "msbc.h"
#include "sco_hci.h"

#if defined(CONFIG_HFP_AUDIO_PATH_SCO_HCI)

/*
 * HFP programs Voice_Setting with linear 16-bit PCM for both CVSD and
 * transparent air coding. For CVSD air mode the controller runs CVSD on the air
 * interface, so HCI SCO payloads carry plain PCM. For transparent air mode the
 * host exchanges mSBC frames prefixed with an H2 header.
 *
 * Speaker data comes from the SCO link and is queued for the codec DAC, while
 * microphone data captured by the codec ADC is queued for the SCO link.
 *
 * The payload length of the (e)SCO link is negotiated by the controllers and is
 * not necessarily one mSBC frame, so mSBC frames are reassembled on receive and
 * sliced into payload sized chunks on transmit.
 */

/* Default CVSD/PCM SCO payload: 60 bytes = 30 samples @ 8 kHz (3.75 ms) */
#define CVSD_SCO_PKT_LEN_DEFAULT 60U
#define CVSD_SAMPLE_RATE         8000U
#define CVSD_CODEC_SAMPLES       160U /* 20 ms codec DMA block */

#define MSBC_SAMPLE_RATE 16000U

#define MAX_SCO_PKT_LEN     MAX(MSBC_SCO_PKT_LEN, CONFIG_BT_BUF_SCO_TX_SIZE)
#define MAX_PCM_SAMPLES     MAX(MAX(CVSD_CODEC_SAMPLES, MSBC_PCM_SAMPLES), MAX_SCO_PKT_LEN / 2U)
#define MAX_PCM_BLOCK_BYTES (MAX_PCM_SAMPLES * sizeof(int16_t))
#define RING_BUF_SIZE       (MAX_PCM_BLOCK_BYTES * 4U)

/* Report a silent link once instead of on every transmit interval */
#define RX_STALL_TIMEOUT_US 1000000U

static struct bt_conn *active_conn;
static struct k_work_delayable tx_work;
static bool tx_running;
static uint8_t air_mode;
static uint16_t sco_pkt_len;
static uint16_t codec_pcm_samples;
static uint32_t sample_rate;
static uint32_t xfer_interval_us;
static uint32_t rx_pkts;
static uint32_t tx_elapsed_us;
static bool rx_stall_reported;
static bool tx_err_reported;

static int16_t enc_block[MAX_PCM_SAMPLES];
static uint8_t tx_pkt[MAX_SCO_PKT_LEN];

/* mSBC frame being sliced into SCO payloads, and stream being reassembled */
static uint8_t tx_frame[MSBC_SCO_PKT_LEN];
static uint16_t tx_frame_len;
static uint16_t tx_frame_pos;
static uint8_t rx_stream[2U * MSBC_SCO_PKT_LEN];
static uint16_t rx_stream_len;

#if DT_HAS_ALIAS(codec0)
static const struct device *codec_dev = DEVICE_DT_GET(DT_ALIAS(codec0));
static uint8_t spk_buffer[RING_BUF_SIZE];
static uint8_t mic_buffer[RING_BUF_SIZE];
static struct ring_buf spk_rb;
static struct ring_buf mic_rb;
static int16_t dac_block[MAX_PCM_SAMPLES];
static bool codec_ready;
static bool spk_playing;

static void codec_tx_done(const struct device *dev, void *user_data)
{
	uint32_t block_bytes = codec_pcm_samples * sizeof(int16_t);
	uint32_t read;

	ARG_UNUSED(user_data);

	/* Build up a small backlog before playing to ride out SCO jitter */
	if (!spk_playing) {
		if (ring_buf_size_get(&spk_rb) < (block_bytes * 2U)) {
			memset(dac_block, 0, block_bytes);
			(void)audio_codec_write(dev, (uint8_t *)dac_block, block_bytes);
			return;
		}

		spk_playing = true;
	}

	read = ring_buf_get(&spk_rb, (uint8_t *)dac_block, block_bytes);
	if (read < block_bytes) {
		memset((uint8_t *)dac_block + read, 0, block_bytes - read);
		spk_playing = false;
	}

	(void)audio_codec_write(dev, (uint8_t *)dac_block, block_bytes);
}

static void codec_rx_done(const struct device *dev, uint8_t *buf, uint32_t len, void *user_data)
{
	ARG_UNUSED(dev);
	ARG_UNUSED(user_data);

	if (ring_buf_put(&mic_rb, buf, len) != len) {
		/* SCO link cannot keep up with the microphone, restart buffering */
		ring_buf_reset(&mic_rb);
	}
}

static int codec_configure(void)
{
	uint32_t block_bytes = codec_pcm_samples * sizeof(int16_t);
	audio_property_value_t vol = {.vol = 15};
	struct audio_codec_cfg cfg = {
		.dai_type = AUDIO_DAI_TYPE_PCM,
		.dai_cfg.pcm.dir = AUDIO_DAI_DIR_TXRX,
		.dai_cfg.pcm.pcm_width = AUDIO_PCM_WIDTH_16_BITS,
		.dai_cfg.pcm.channels = 1U,
		.dai_cfg.pcm.block_size = block_bytes,
		.dai_cfg.pcm.samplerate = sample_rate,
	};
	int err;

	if (!device_is_ready(codec_dev)) {
		printk("Codec device not ready\n");
		return -ENODEV;
	}

	ring_buf_init(&spk_rb, RING_BUF_SIZE, spk_buffer);
	ring_buf_init(&mic_rb, RING_BUF_SIZE, mic_buffer);
	spk_playing = false;

	audio_codec_register_done_callback(codec_dev, codec_tx_done, NULL, codec_rx_done, NULL);

	err = audio_codec_configure(codec_dev, &cfg);
	if (err != 0) {
		return err;
	}

	err = audio_codec_start(codec_dev, AUDIO_DAI_DIR_TXRX);
	if (err != 0) {
		return err;
	}

	err = audio_codec_set_property(codec_dev, AUDIO_PROPERTY_OUTPUT_VOLUME, 0, vol);
	if (err != 0) {
		return err;
	}

	codec_ready = true;
	return 0;
}

static void codec_release(void)
{
	if (!codec_ready) {
		return;
	}

	(void)audio_codec_stop(codec_dev, AUDIO_DAI_DIR_TXRX);
	codec_ready = false;
	spk_playing = false;
}

static void play_pcm(const int16_t *samples, size_t count)
{
	uint32_t bytes = count * sizeof(int16_t);

	if (!codec_ready) {
		return;
	}

	if (ring_buf_put(&spk_rb, (const uint8_t *)samples, bytes) != bytes) {
		printk("Speaker ring buffer full\n");
	}
}

static void capture_pcm(int16_t *samples, size_t count)
{
	uint32_t bytes = count * sizeof(int16_t);
	uint32_t read = 0;

	if (codec_ready) {
		read = ring_buf_get(&mic_rb, (uint8_t *)samples, bytes);
	}

	if (read < bytes) {
		memset((uint8_t *)samples + read, 0, bytes - read);
	}
}
#else
static int codec_configure(void)
{
	return 0;
}

static void codec_release(void)
{
}

static void play_pcm(const int16_t *samples, size_t count)
{
	ARG_UNUSED(samples);
	ARG_UNUSED(count);
}

static void capture_pcm(int16_t *samples, size_t count)
{
	memset(samples, 0, count * sizeof(int16_t));
}
#endif /* DT_HAS_ALIAS(codec0) */

static bool air_mode_is_msbc(uint8_t mode)
{
	return mode == BT_HCI_CODING_FORMAT_TRANSPARENT && IS_ENABLED(CONFIG_HFP_SCO_HCI_MSBC);
}

/* Adopt the payload length the controller actually uses for this link */
static void update_sco_pkt_len(uint16_t len)
{
	if (len < 2U || len > MAX_SCO_PKT_LEN || len == sco_pkt_len) {
		return;
	}

	if (air_mode == BT_HCI_CODING_FORMAT_CVSD) {
		if ((len & 1U) != 0U) {
			return;
		}

		xfer_interval_us = ((len / sizeof(int16_t)) * 1000000U) / sample_rate;
	} else {
		xfer_interval_us = (len * 1000000U) / MSBC_BYTE_RATE;
	}

	sco_pkt_len = len;
	printk("SCO payload %u bytes (%u us)\n", sco_pkt_len, xfer_interval_us);
}

static int setup_air_mode(uint8_t mode)
{
	int err;

	air_mode = mode;
	rx_pkts = 0U;
	rx_stream_len = 0U;
	tx_frame_len = 0U;
	tx_frame_pos = 0U;
	tx_elapsed_us = 0U;
	rx_stall_reported = false;
	tx_err_reported = false;

	if (mode == BT_HCI_CODING_FORMAT_CVSD) {
		sco_pkt_len = CVSD_SCO_PKT_LEN_DEFAULT;
		codec_pcm_samples = CVSD_CODEC_SAMPLES;
		sample_rate = CVSD_SAMPLE_RATE;
		xfer_interval_us = ((sco_pkt_len / sizeof(int16_t)) * 1000000U) / sample_rate;
	} else if (air_mode_is_msbc(mode)) {
		sco_pkt_len = MSBC_SCO_PKT_LEN;
		codec_pcm_samples = MSBC_PCM_SAMPLES;
		sample_rate = MSBC_SAMPLE_RATE;
		xfer_interval_us = MSBC_FRAME_DURATION_US;
		err = msbc_init();
		if (err != 0) {
			printk("Failed to init mSBC: %d\n", err);
			return err;
		}
	} else {
		printk("Unsupported SCO air mode: %u\n", mode);
		return -ENOTSUP;
	}

	return codec_configure();
}

/* Reassemble mSBC frames from the SCO byte stream and play what decodes */
static void msbc_stream_recv(const uint8_t *data, uint16_t len)
{
	int16_t pcm[MSBC_PCM_SAMPLES];
	uint16_t chunk;
	int decoded;
	int offset;

	while (len > 0U) {
		chunk = MIN(len, (uint16_t)(sizeof(rx_stream) - rx_stream_len));
		if (chunk == 0U) {
			rx_stream_len = 0U;
			continue;
		}

		memcpy(&rx_stream[rx_stream_len], data, chunk);
		rx_stream_len += chunk;
		data += chunk;
		len -= chunk;

		while (rx_stream_len > 0U) {
			offset = msbc_frame_sync(rx_stream, rx_stream_len);
			if (offset < 0) {
				/* Keep the last byte, it may start an H2 header */
				rx_stream[0] = rx_stream[rx_stream_len - 1U];
				rx_stream_len = 1U;
				break;
			}

			rx_stream_len -= (uint16_t)offset;
			memmove(rx_stream, &rx_stream[offset], rx_stream_len);

			if (rx_stream_len < MSBC_SCO_PKT_LEN) {
				break;
			}

			decoded = msbc_decode(rx_stream, MSBC_SCO_PKT_LEN, pcm, ARRAY_SIZE(pcm));
			rx_stream_len -= MSBC_SCO_PKT_LEN;
			memmove(rx_stream, &rx_stream[MSBC_SCO_PKT_LEN], rx_stream_len);

			if (decoded > 0) {
				play_pcm(pcm, (size_t)decoded);
			}
		}
	}
}

static void sco_recv(struct bt_conn *conn, struct net_buf *buf)
{
	uint16_t len = buf->len;

	if (conn != active_conn) {
		net_buf_unref(buf);
		return;
	}

	rx_pkts++;
	update_sco_pkt_len(len);

	if (air_mode == BT_HCI_CODING_FORMAT_CVSD) {
		if (len >= 2U && (len & 1U) == 0U) {
			play_pcm((const int16_t *)buf->data, len / sizeof(int16_t));
		}
	} else if (air_mode_is_msbc(air_mode)) {
		msbc_stream_recv(buf->data, len);
	}

	net_buf_unref(buf);
}

static void tx_work_handler(struct k_work *work)
{
	struct net_buf *buf;
	uint32_t interval_us = xfer_interval_us;
	int err;
	int pkt_len;

	ARG_UNUSED(work);

	if (!tx_running || active_conn == NULL) {
		return;
	}

	if (air_mode == BT_HCI_CODING_FORMAT_CVSD) {
		pkt_len = sco_pkt_len;
		capture_pcm(enc_block, sco_pkt_len / sizeof(int16_t));
		memcpy(tx_pkt, enc_block, sco_pkt_len);
	} else if (air_mode_is_msbc(air_mode)) {
		if (tx_frame_pos >= tx_frame_len) {
			capture_pcm(enc_block, MSBC_PCM_SAMPLES);
			err = msbc_encode(enc_block, MSBC_PCM_SAMPLES, tx_frame, sizeof(tx_frame));
			if (err < 0) {
				k_work_schedule(&tx_work, K_USEC(interval_us));
				return;
			}

			tx_frame_len = (uint16_t)err;
			tx_frame_pos = 0U;
		}

		pkt_len = MIN(sco_pkt_len, tx_frame_len - tx_frame_pos);
		memcpy(tx_pkt, &tx_frame[tx_frame_pos], pkt_len);
		interval_us = ((uint32_t)pkt_len * 1000000U) / MSBC_BYTE_RATE;
	} else {
		return;
	}

	buf = bt_sco_buf_alloc(K_NO_WAIT);
	if (buf == NULL) {
		k_work_schedule(&tx_work, K_USEC(interval_us));
		return;
	}

	if (air_mode_is_msbc(air_mode)) {
		tx_frame_pos += pkt_len;
	}

	net_buf_add_mem(buf, tx_pkt, pkt_len);
	err = bt_sco_send(active_conn, buf);
	if (err != 0 && !tx_err_reported) {
		tx_err_reported = true;
		printk("Failed to send SCO data: %d\n", err);
	}

	tx_elapsed_us += interval_us;
	if (rx_pkts == 0U && !rx_stall_reported && tx_elapsed_us > RX_STALL_TIMEOUT_US) {
		rx_stall_reported = true;
		printk("No SCO data received from the controller\n");
	}

	k_work_schedule(&tx_work, K_USEC(interval_us));
}

int sco_hci_init(uint8_t mode)
{
	int err;

	err = setup_air_mode(mode);
	if (err != 0) {
		return err;
	}

	k_work_init_delayable(&tx_work, tx_work_handler);

	return 0;
}

int sco_hci_start(struct bt_conn *sco_conn)
{
	int err;

	err = bt_sco_recv_cb_set(sco_conn, sco_recv);
	if (err != 0) {
		return err;
	}

	active_conn = bt_conn_ref(sco_conn);
	tx_running = true;
	k_work_schedule(&tx_work, K_USEC(xfer_interval_us));
	return 0;
}

int sco_hci_stop(void)
{
	tx_running = false;
	k_work_cancel_delayable(&tx_work);

	if (active_conn != NULL) {
		(void)bt_sco_recv_cb_set(active_conn, NULL);
		bt_conn_unref(active_conn);
		active_conn = NULL;
	}

	codec_release();

	return 0;
}

#else

int sco_hci_init(uint8_t air_mode)
{
	ARG_UNUSED(air_mode);
	return -ENOTSUP;
}

int sco_hci_start(struct bt_conn *sco_conn)
{
	ARG_UNUSED(sco_conn);
	return -ENOTSUP;
}

int sco_hci_stop(void)
{
	return 0;
}

#endif /* CONFIG_HFP_AUDIO_PATH_SCO_HCI */
```
